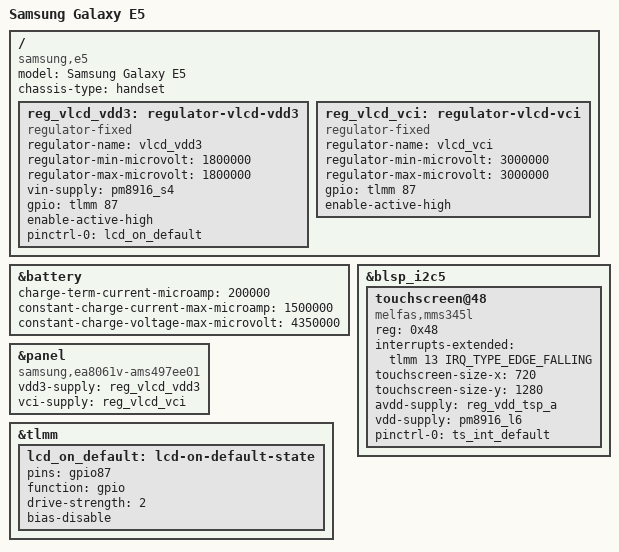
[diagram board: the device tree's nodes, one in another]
// SPDX-License-Identifier: GPL-2.0-only

/dts-v1/;

#include "msm8916-samsung-e2015-common.dtsi"

/*
 * NOTE: The original firmware from Samsung can only boot ARM32 kernels on some
 * variants.
 * Unfortunately, the firmware is signed and cannot be replaced easily.
 * There seems to be no way to boot ARM64 kernels on 32-bit devices at the
 * moment, even though the hardware would support it.
 *
 * However, it is possible to use this device tree by compiling an ARM32 kernel
 * instead. For clarity and build testing this device tree is maintained next
 * to the other MSM8916 device trees. However, it is actually used through
 * arch/arm/boot/dts/qcom-msm8916-samsung-e5.dts
 */

/ {
	model = "Samsung Galaxy E5";
	compatible = "samsung,e5", "qcom,msm8916";
	chassis-type = "handset";

	reg_vlcd_vdd3: regulator-vlcd-vdd3 {
		compatible = "regulator-fixed";
		regulator-name = "vlcd_vdd3";
		regulator-min-microvolt = <1800000>;
		regulator-max-microvolt = <1800000>;
		vin-supply = <&pm8916_s4>;

		gpio = <&tlmm 87 GPIO_ACTIVE_HIGH>;
		enable-active-high;

		pinctrl-0 = <&lcd_on_default>;
		pinctrl-names = "default";
	};

	reg_vlcd_vci: regulator-vlcd-vci {
		compatible = "regulator-fixed";
		regulator-name = "vlcd_vci";
		regulator-min-microvolt = <3000000>;
		regulator-max-microvolt = <3000000>;

		gpio = <&tlmm 87 GPIO_ACTIVE_HIGH>;
		enable-active-high;
	};
};

&battery {
	charge-term-current-microamp = <200000>;
	constant-charge-current-max-microamp = <1500000>;
	constant-charge-voltage-max-microvolt = <4350000>;
};

&blsp_i2c5 {
	status = "okay";

	touchscreen@48 {
		compatible = "melfas,mms345l";
		reg = <0x48>;

		interrupts-extended = <&tlmm 13 IRQ_TYPE_EDGE_FALLING>;

		touchscreen-size-x = <720>;
		touchscreen-size-y = <1280>;

		avdd-supply = <&reg_vdd_tsp_a>;
		vdd-supply = <&pm8916_l6>;

		pinctrl-0 = <&ts_int_default>;
		pinctrl-names = "default";
	};
};

&panel {
	/* Actually samsung,ea8061v-ams497ee10 */
	compatible = "samsung,ea8061v-ams497ee01";

	vdd3-supply = <&reg_vlcd_vdd3>;
	vci-supply = <&reg_vlcd_vci>;
};

&tlmm {
	lcd_on_default: lcd-on-default-state {
		pins = "gpio87";
		function = "gpio";
		drive-strength = <2>;
		bias-disable;
	};
};
